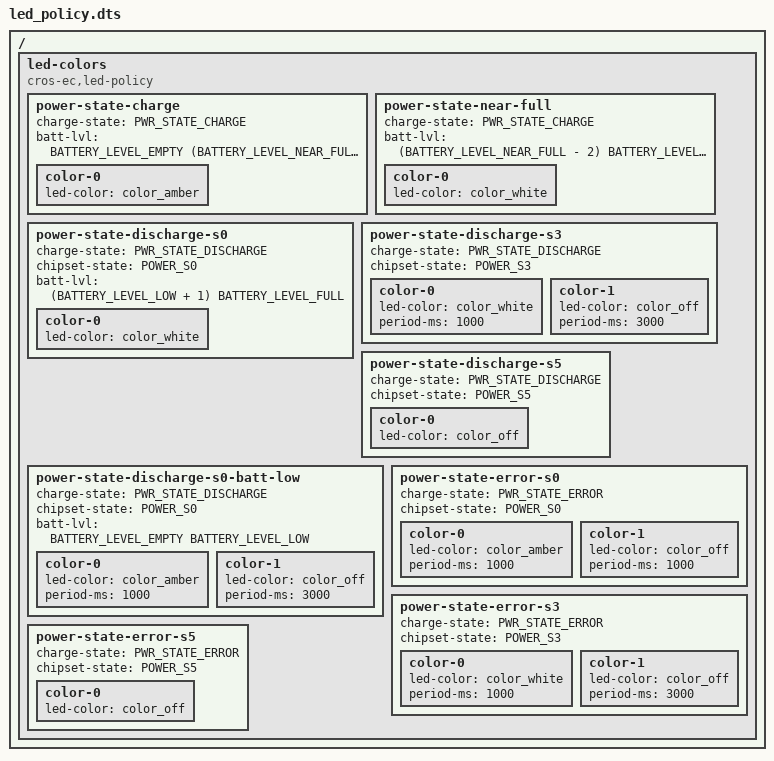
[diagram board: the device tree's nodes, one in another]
#include <dt-bindings/battery.h>

/ {
	led-colors {
		compatible = "cros-ec,led-policy";

		power-state-charge {
			charge-state = "PWR_STATE_CHARGE";
			/* Battery percent range (>= Empty, <= 94%) */
			batt-lvl = <BATTERY_LEVEL_EMPTY
				   (BATTERY_LEVEL_NEAR_FULL - 3)>;

			color-0 {
				led-color = <&color_amber>;
			};
		};

		power-state-near-full {
			charge-state = "PWR_STATE_CHARGE";
			/* Battery percent range (>= 95%, <= Full) */
			batt-lvl = <(BATTERY_LEVEL_NEAR_FULL - 2)
				     BATTERY_LEVEL_FULL>;

			color-0 {
				led-color = <&color_white>;
			};
		};

		power-state-discharge-s0 {
			charge-state = "PWR_STATE_DISCHARGE";
			chipset-state = "POWER_S0";
			/* Battery percent range (>= 11%, <= Full) */
			batt-lvl = <(BATTERY_LEVEL_LOW + 1)
				     BATTERY_LEVEL_FULL>;

			color-0 {
				led-color = <&color_white>;
			};
		};

		power-state-discharge-s3 {
			charge-state = "PWR_STATE_DISCHARGE";
			chipset-state = "POWER_S3";

			/* White 1 sec, off 3 sec */
			color-0 {
				led-color = <&color_white>;
				period-ms = <1000>;
			};
			color-1 {
				led-color = <&color_off>;
				period-ms = <3000>;
			};
		};

		power-state-discharge-s5 {
			charge-state = "PWR_STATE_DISCHARGE";
			chipset-state = "POWER_S5";

			color-0 {
				led-color = <&color_off>;
			};
		};

		power-state-discharge-s0-batt-low {
			charge-state = "PWR_STATE_DISCHARGE";
			chipset-state = "POWER_S0";
			/* Battery percent range (>= Empty, <= 10%) */
			batt-lvl = <BATTERY_LEVEL_EMPTY BATTERY_LEVEL_LOW>;

			/* Amber 1 sec, off 3 sec */
			color-0 {
				led-color = <&color_amber>;
				period-ms = <1000>;
			};
			color-1 {
				led-color = <&color_off>;
				period-ms = <3000>;
			};
		};

		power-state-error-s0 {
			charge-state = "PWR_STATE_ERROR";
			chipset-state = "POWER_S0";
			/* Amber 1 sec, off 1 sec */
			color-0 {
				led-color = <&color_amber>;
				period-ms = <1000>;
			};
			color-1 {
				led-color = <&color_off>;
				period-ms = <1000>;
			};
		};

		power-state-error-s3 {
			charge-state = "PWR_STATE_ERROR";
			chipset-state = "POWER_S3";
			/* White 1 sec, off 3 sec */
			color-0 {
				led-color = <&color_white>;
				period-ms = <1000>;
			};
			color-1 {
				led-color = <&color_off>;
				period-ms = <3000>;
			};
		};

		power-state-error-s5 {
			charge-state = "PWR_STATE_ERROR";
			chipset-state = "POWER_S5";

			color-0 {
				led-color = <&color_off>;
			};
		};
	};
};
